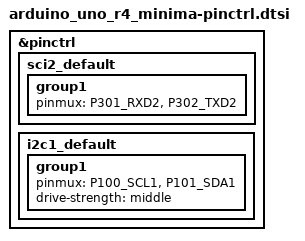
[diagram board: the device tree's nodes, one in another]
/*
 * Copyright (c) 2023 TOKITA Hiroshi <tokita.hiroshi@fujitsu.com>
 *
 * SPDX-License-Identifier: Apache-2.0
 */

#include <zephyr/dt-bindings/pinctrl/renesas/pinctrl-r7fa4m1xxxxxx.h>

&pinctrl {
	sci2_default: sci2_default {
		group1 {
			pinmux = <P301_RXD2>, <P302_TXD2>;
		};
	};

	i2c1_default: i2c1_default {
		group1 {
			pinmux = <P100_SCL1>, <P101_SDA1>;
			drive-strength = "middle";
		};
	};
};
